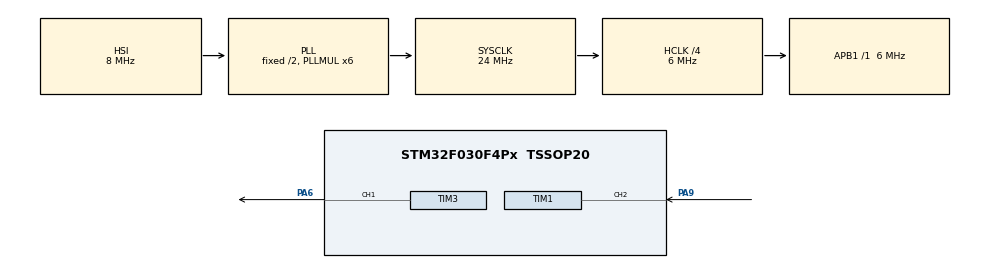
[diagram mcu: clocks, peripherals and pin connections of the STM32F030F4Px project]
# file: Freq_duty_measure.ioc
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Mcu.Family=STM32F0
Mcu.Name=STM32F030F4Px
Mcu.Package=TSSOP20
NVIC.TIM1_BRK_UP_TRG_COM_IRQn=true\:0\:0\:false\:false\:true\:true\:true\:true
NVIC.TIM1_CC_IRQn=true\:1\:0\:true\:false\:true\:true\:true\:true
PA13.Mode=Serial_Wire
PA13.Signal=SYS_SWDIO
PA14.Mode=Serial_Wire
PA14.Signal=SYS_SWCLK
PA6.Signal=S_TIM3_CH1
PA9.Signal=S_TIM1_CH2
ProjectManager.HeapSize=0x200
ProjectManager.StackSize=0x400
ProjectManager.TargetToolchain=STM32CubeIDE
RCC.AHBCLKDivider=RCC_SYSCLK_DIV4
RCC.AHBFreq_Value=6000000
RCC.APB1Freq_Value=6000000
RCC.APB1TimFreq_Value=6000000
RCC.HCLKFreq_Value=6000000
RCC.PLLMUL=RCC_PLL_MUL6
RCC.SYSCLKFreq_VALUE=24000000
RCC.SYSCLKSource=RCC_SYSCLKSOURCE_PLLCLK
SH.S_TIM1_CH2.0=TIM1_CH2,Input_Capture2_from_TI2
SH.S_TIM3_CH1.0=TIM3_CH1,PWM Generation1 CH1
TIM1.Channel-Input_Capture2_from_TI2=TIM_CHANNEL_2
TIM1.Period=65535
TIM1.Prescaler=50-1
TIM3.Channel-PWM\ Generation1\ CH1=TIM_CHANNEL_1
TIM3.Period=100-1
TIM3.Prescaler=50-1
VP_TIM1_VS_ClockSourceINT.Mode=Internal
VP_TIM3_VS_ClockSourceINT.Mode=Internal
board=custom

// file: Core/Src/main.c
/* USER CODE BEGIN Header */
/**
  ******************************************************************************
  * @file           : main.c
  * @brief          : Main program body
  ******************************************************************************
  * @attention
  *
  * Copyright (c) 2023 STMicroelectronics.
  * All rights reserved.
  *
  * This software is licensed under terms that can be found in the LICENSE file
  * in the root directory of this software component.
  * If no LICENSE file comes with this software, it is provided AS-IS.
  *
  ******************************************************************************
  */
/* USER CODE END Header */
#include "main.h"

TIM_HandleTypeDef htim1;
TIM_HandleTypeDef htim3;

void SystemClock_Config(void);
static void MX_GPIO_Init(void);
static void MX_TIM3_Init(void);
static void MX_TIM1_Init(void);

/* USER CODE BEGIN 0 */
unsigned int duty_debug=5;
uint8_t capture_flag=0;
uint8_t compute_flag=0;
volatile uint8_t timer1_update_count=0;
uint32_t freq_width;
float duty_width;

volatile uint32_t middle;
volatile uint16_t start;
volatile uint16_t stop;

float duty;
uint16_t frequency;

float reference=12e4;
/* USER CODE END 0 */

int main(void)
{

  /* MCU Configuration--------------------------------------------------------*/

  /* Reset of all peripherals, Initializes the Flash interface and the Systick. */
  HAL_Init();

  /* Configure the system clock */
  SystemClock_Config();

  /* Initialize all configured peripherals */
  MX_GPIO_Init();
  MX_TIM3_Init();
  MX_TIM1_Init();
  /* USER CODE BEGIN 2 */
  HAL_TIM_PWM_Start(&htim3,TIM_CHANNEL_1);

  HAL_TIM_IC_Start_IT(&htim1, TIM_CHANNEL_2);
  HAL_TIM_Base_Start_IT(&htim1);
  /* USER CODE END 2 */

  /* Infinite loop */
  while (1)
  {

    /* USER CODE BEGIN 3 */
	  TIM3->CCR1=duty_debug;
	  if(compute_flag){
		  freq_width=stop-start;
		  duty_width=(float) (middle-start);
		  frequency=reference/freq_width;
		  duty= duty_width/freq_width*100;
	      compute_flag=0;
	  }

  }
  /* USER CODE END 3 */
}

void SystemClock_Config(void)
{
  RCC_OscInitTypeDef RCC_OscInitStruct = {0};
  RCC_ClkInitTypeDef RCC_ClkInitStruct = {0};

  /** Initializes the RCC Oscillators according to the specified parameters
  * in the RCC_OscInitTypeDef structure.
  */
  RCC_OscInitStruct.OscillatorType = RCC_OSCILLATORTYPE_HSI;
  RCC_OscInitStruct.HSIState = RCC_HSI_ON;
  RCC_OscInitStruct.HSICalibrationValue = RCC_HSICALIBRATION_DEFAULT;
  RCC_OscInitStruct.PLL.PLLState = RCC_PLL_ON;
  RCC_OscInitStruct.PLL.PLLSource = RCC_PLLSOURCE_HSI;
  RCC_OscInitStruct.PLL.PLLMUL = RCC_PLL_MUL6;
  RCC_OscInitStruct.PLL.PREDIV = RCC_PREDIV_DIV1;
  if (HAL_RCC_OscConfig(&RCC_OscInitStruct) != HAL_OK)
  {
    Error_Handler();
  }

  /** Initializes the CPU, AHB and APB buses clocks
  */
  RCC_ClkInitStruct.ClockType = RCC_CLOCKTYPE_HCLK|RCC_CLOCKTYPE_SYSCLK
                              |RCC_CLOCKTYPE_PCLK1;
  RCC_ClkInitStruct.SYSCLKSource = RCC_SYSCLKSOURCE_PLLCLK;
  RCC_ClkInitStruct.AHBCLKDivider = RCC_SYSCLK_DIV4;
  RCC_ClkInitStruct.APB1CLKDivider = RCC_HCLK_DIV1;

  if (HAL_RCC_ClockConfig(&RCC_ClkInitStruct, FLASH_LATENCY_0) != HAL_OK)
  {
    Error_Handler();
  }
}

static void MX_TIM1_Init(void)
{

  TIM_ClockConfigTypeDef sClockSourceConfig = {0};
  TIM_MasterConfigTypeDef sMasterConfig = {0};
  TIM_IC_InitTypeDef sConfigIC = {0};

  htim1.Instance = TIM1;
  htim1.Init.Prescaler = 50-1;
  htim1.Init.CounterMode = TIM_COUNTERMODE_UP;
  htim1.Init.Period = 65535;
  htim1.Init.ClockDivision = TIM_CLOCKDIVISION_DIV1;
  htim1.Init.RepetitionCounter = 0;
  htim1.Init.AutoReloadPreload = TIM_AUTORELOAD_PRELOAD_DISABLE;
  if (HAL_TIM_Base_Init(&htim1) != HAL_OK)
  {
    Error_Handler();
  }
  sClockSourceConfig.ClockSource = TIM_CLOCKSOURCE_INTERNAL;
  if (HAL_TIM_ConfigClockSource(&htim1, &sClockSourceConfig) != HAL_OK)
  {
    Error_Handler();
  }
  if (HAL_TIM_IC_Init(&htim1) != HAL_OK)
  {
    Error_Handler();
  }
  sMasterConfig.MasterOutputTrigger = TIM_TRGO_RESET;
  sMasterConfig.MasterSlaveMode = TIM_MASTERSLAVEMODE_DISABLE;
  if (HAL_TIMEx_MasterConfigSynchronization(&htim1, &sMasterConfig) != HAL_OK)
  {
    Error_Handler();
  }
  sConfigIC.ICPolarity = TIM_INPUTCHANNELPOLARITY_RISING;
  sConfigIC.ICSelection = TIM_ICSELECTION_DIRECTTI;
  sConfigIC.ICPrescaler = TIM_ICPSC_DIV1;
  sConfigIC.ICFilter = 0;
  if (HAL_TIM_IC_ConfigChannel(&htim1, &sConfigIC, TIM_CHANNEL_2) != HAL_OK)
  {
    Error_Handler();
  }

}

static void MX_TIM3_Init(void)
{

  TIM_ClockConfigTypeDef sClockSourceConfig = {0};
  TIM_MasterConfigTypeDef sMasterConfig = {0};
  TIM_OC_InitTypeDef sConfigOC = {0};

  htim3.Instance = TIM3;
  htim3.Init.Prescaler = 50-1;
  htim3.Init.CounterMode = TIM_COUNTERMODE_UP;
  htim3.Init.Period = 100-1;
  htim3.Init.ClockDivision = TIM_CLOCKDIVISION_DIV1;
  htim3.Init.AutoReloadPreload = TIM_AUTORELOAD_PRELOAD_DISABLE;
  if (HAL_TIM_Base_Init(&htim3) != HAL_OK)
  {
    Error_Handler();
  }
  sClockSourceConfig.ClockSource = TIM_CLOCKSOURCE_INTERNAL;
  if (HAL_TIM_ConfigClockSource(&htim3, &sClockSourceConfig) != HAL_OK)
  {
    Error_Handler();
  }
  if (HAL_TIM_PWM_Init(&htim3) != HAL_OK)
  {
    Error_Handler();
  }
  sMasterConfig.MasterOutputTrigger = TIM_TRGO_RESET;
  sMasterConfig.MasterSlaveMode = TIM_MASTERSLAVEMODE_DISABLE;
  if (HAL_TIMEx_MasterConfigSynchronization(&htim3, &sMasterConfig) != HAL_OK)
  {
    Error_Handler();
  }
  sConfigOC.OCMode = TIM_OCMODE_PWM1;
  sConfigOC.Pulse = 0;
  sConfigOC.OCPolarity = TIM_OCPOLARITY_HIGH;
  sConfigOC.OCFastMode = TIM_OCFAST_DISABLE;
  if (HAL_TIM_PWM_ConfigChannel(&htim3, &sConfigOC, TIM_CHANNEL_1) != HAL_OK)
  {
    Error_Handler();
  }
  HAL_TIM_MspPostInit(&htim3);

}

static void MX_GPIO_Init(void)
{

  /* GPIO Ports Clock Enable */
  __HAL_RCC_GPIOA_CLK_ENABLE();

}

/* USER CODE BEGIN 4 */
void HAL_TIM_IC_CaptureCallback(TIM_HandleTypeDef *htim){
    /*
	if(capture_flag==0){
		timer1_update_count=0;
		start =TIM1->CCR2;
		//start = HAL_TIM_ReadCapturedValue(htim, TIM_CHANNEL_2);
		capture_flag=1;
	}else{
			//stop =HAL_TIM_ReadCapturedValue(htim, TIM_CHANNEL_2); The code below does the same and saves space!!!
		    stop =TIM1->CCR2;
			freq_width = TIM1->ARR*(timer1_update_count)-start+stop;
			compute_flag=1;
			capture_flag=0;
					}
	*/

		if(capture_flag==0){
			timer1_update_count=0;
			start =TIM1->CCR2;
			__HAL_TIM_SET_CAPTUREPOLARITY(htim, TIM_CHANNEL_2, TIM_INPUTCHANNELPOLARITY_FALLING);
			capture_flag++;
		}else if(capture_flag==1){
			middle = TIM1->ARR*(timer1_update_count)+TIM1->CCR2;
			__HAL_TIM_SET_CAPTUREPOLARITY(htim, TIM_CHANNEL_2, TIM_INPUTCHANNELPOLARITY_RISING);
			capture_flag++;
		}else{
			  stop = TIM1->ARR*(timer1_update_count)+TIM1->CCR2;
			  capture_flag=0;
			  compute_flag=1;
		   }

}

void HAL_TIM_PeriodElapsedCallback(TIM_HandleTypeDef* htim)
{

	timer1_update_count++;

}

/* USER CODE END 4 */

void Error_Handler(void)
{
  __disable_irq();
  while (1)
  {
  }
}
